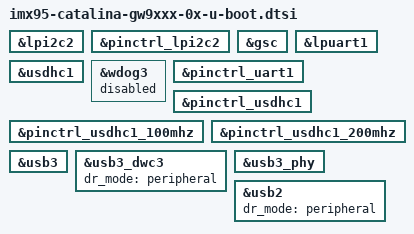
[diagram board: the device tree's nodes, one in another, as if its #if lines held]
// SPDX-License-Identifier: GPL-2.0+
/*
 * Copyright 2025 Gateworks
 */

#include "imx95-u-boot.dtsi"

&lpi2c2 {
	bootph-pre-ram;
};

&pinctrl_lpi2c2 {
	bootph-pre-ram;
};

&gsc {
	bootph-pre-ram;
};

&lpuart1 {
	bootph-pre-ram;
};

&usdhc1 {
	bootph-pre-ram;
};

&wdog3 {
	status = "disabled";
};

&pinctrl_uart1 {
	bootph-pre-ram;
};

&pinctrl_usdhc1 {
	bootph-pre-ram;
};

&pinctrl_usdhc1_100mhz {
	bootph-pre-ram;
};

&pinctrl_usdhc1_200mhz {
	bootph-pre-ram;
};

#ifdef CONFIG_SPL_USB_SDP_SUPPORT
/* Note i.MX95 BOOT ROM supports SDP over USB1 (usb3 node) or USB2 (usb2 node) interface (not both)
 * depending on the specific part number ordered (which is not detectable via markings or software)
 */

/* support SDP over USB1 interface */
&usb3 {
	bootph-pre-ram;
	status = "okay";
};

&usb3_dwc3 {
	bootph-pre-ram;
	dr_mode = "peripheral";
	status = "okay";
};

&usb3_phy {
	bootph-pre-ram;
	status = "okay";
};

/* support SDP over USB2 interface */
&usb2 {
	bootph-pre-ram;
	dr_mode = "peripheral";
	status = "okay";
};
#endif

